# SMS0_DMTIMER_2_DMTIMER2 register map
Vendor: Texas Instruments
Peripheral module from a debugger description file (folder am62P).
Registers are 32-bit, read-write, reset 0x0 unless marked. A register's access mark holds for its fields unless they carry their own. Offsets are as the file gives them; lines under a group give offsets from that group; [hi:lo] are bit positions; {n}, {i} and the like mark numbered series; 'fields as' and 'values as' point back to an identical list; <NAME> marks a mode.

## SMS0_DMTIMER_2_DMTIMER2
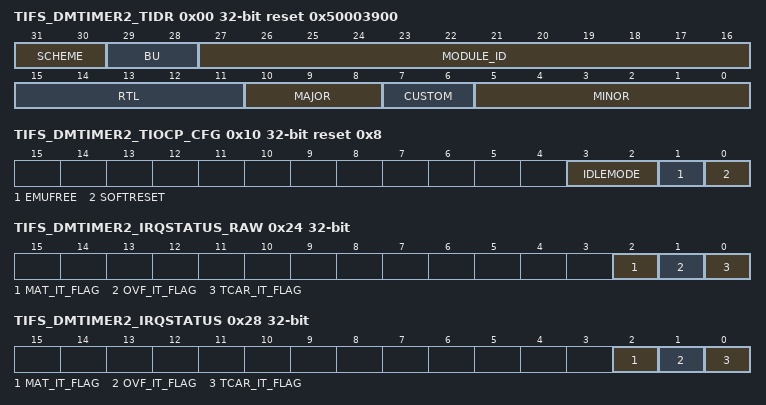
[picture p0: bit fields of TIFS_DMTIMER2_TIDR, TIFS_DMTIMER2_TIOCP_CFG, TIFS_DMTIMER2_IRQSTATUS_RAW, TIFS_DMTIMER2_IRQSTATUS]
0x00 TIFS_DMTIMER2_TIDR ro reset 0x50003900
  [31:30] SCHEME — PID register scheme
  [29:28] BU — Business Unit
  [27:16] MODULE_ID
  [15:11] RTL — RTL revision. Will vary depending on release.
  [10:8] MAJOR — Major revision
  [7:6] CUSTOM
  [5:0] MINOR — Minor revision
0x10 TIFS_DMTIMER2_TIOCP_CFG reset 0x8 — This register controls the various parameters of the OCP interface
  [3:2] IDLEMODE
  [1] EMUFREE — Emulation Mode
  [0] SOFTRESET — Software reset
0x20 TIFS_DMTIMER2_IRQ_EOI — Allows the generation of further pulses on the interrupt line, if an new interrupt event is pending, when using the pulsed output. Unused when using the level interrupt line
  [0] LINE_NUMBER — Idle Mode
0x24 TIFS_DMTIMER2_IRQSTATUS_RAW access not given — Component interrupt request status. Check the corresponding secondary status register. Raw status is set even if event is not enabled. Write 1 to set the (raw) status, mostly for debug
  [2] MAT_IT_FLAG — Match Interrupt (access R/W1TS)
  [1] OVF_IT_FLAG — Overflow Interrupt (access R/W1TS)
  [0] TCAR_IT_FLAG — Capture Interrupt (access R/W1TS)
0x28 TIFS_DMTIMER2_IRQSTATUS access not given — Component interrupt request status. Check the corresponding secondary status register.Enabled status isn't set unless event is enabled.Write 1 to clear the status after interrupt has been serviced;raw status gets cleared, i.e. even if not enabled
  [2] MAT_IT_FLAG — Match Interrupt (access R/W1TC)
  [1] OVF_IT_FLAG — Overflow Interrupt (access R/W1TC)
  [0] TCAR_IT_FLAG — Capture Interrupt (access R/W1TC)
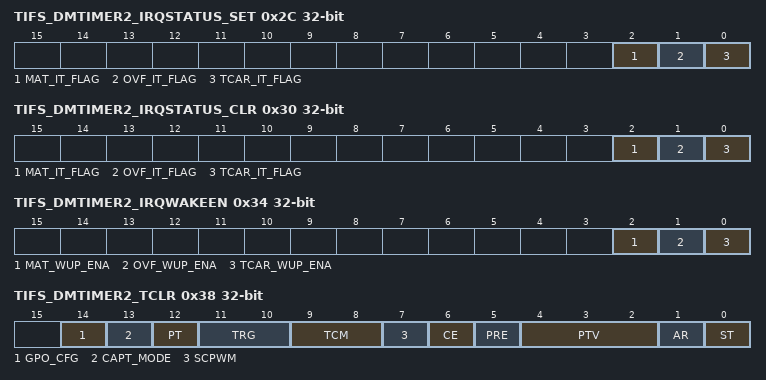
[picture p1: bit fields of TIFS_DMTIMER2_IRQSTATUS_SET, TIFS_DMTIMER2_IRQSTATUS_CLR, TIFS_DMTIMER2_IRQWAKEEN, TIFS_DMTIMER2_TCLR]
0x2C TIFS_DMTIMER2_IRQSTATUS_SET access not given — Component interrupt request enable Write 1 to set, enable interrupt. Readout equal to corresponding _CLR register.
  fields as TIFS_DMTIMER2_IRQSTATUS_RAW
0x30 TIFS_DMTIMER2_IRQSTATUS_CLR access not given — Component interrupt request enable. Write 1 to clear, disable interrupt. Readout equal to corresponding _SET register
  fields as TIFS_DMTIMER2_IRQSTATUS
0x34 TIFS_DMTIMER2_IRQWAKEEN — Wakeup-enabled events taking place when module is idle shall generate an asynchronous wakeup
  [2] MAT_WUP_ENA — Match Wakeup Enable
  [1] OVF_WUP_ENA — Overflow Wakeup Enable
  [0] TCAR_WUP_ENA — Capture Wakeup Enable
0x38 TIFS_DMTIMER2_TCLR — This register controls optional features specific to the timer functionality
  [14] GPO_CFG — This field drives directly the PO_GPOCFG pin
  [13] CAPT_MODE — Capture mode select bit; First/second
  [12] PT — Pulse or Toggle select bit
  [11:10] TRG — Trigger Output Mode
  [9:8] TCM — Transition Capture Mode
  [7] SCPWM — Pulse Width Modulation output pin default value
  [6] CE — Compare Enable
  [5] PRE — Prescaler Enable
  [4:2] PTV — Trigger Output Mode. The timer counter is prescaled with the value: 2^PTV
  [1] AR — Auto-reload mode
  [0] ST — Start/Stop timer control
0x3C TIFS_DMTIMER2_TCRR — This register holds the value of the internal counter
  [31:0] TIMER_COUNTER
0x40 TIFS_DMTIMER2_TLDR — This register holds the timer's load value
  [31:0] LOAD_VALUE — Timer Counter
0x44 TIFS_DMTIMER2_TTGR — This register triggers a counter reload of timer by writing any value in it
  [31:0] TTRG_VLAUE — The value of the trigger register. During reads, it always return 0xFFFF_FFFF
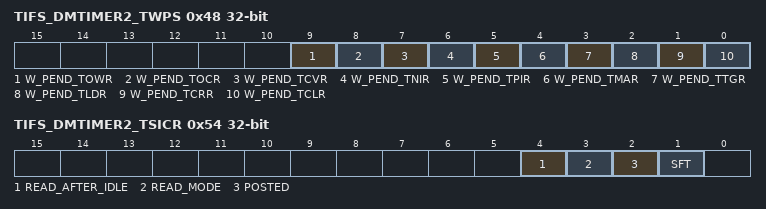
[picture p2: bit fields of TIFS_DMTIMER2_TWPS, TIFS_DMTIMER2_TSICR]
0x48 TIFS_DMTIMER2_TWPS ro — This register contains the write posting bits for all writ-able functional registers
  [9] W_PEND_TOWR — Write pending for register TOWR
  [8] W_PEND_TOCR — Write pending for register TOCR
  [7] W_PEND_TCVR — Write pending for register TCVR
  [6] W_PEND_TNIR — Write pending for register TNIR
  [5] W_PEND_TPIR — Write pending for register TPIR
  [4] W_PEND_TMAR — Write pending for register TMAR
  [3] W_PEND_TTGR — Write pending for register TTGR
  [2] W_PEND_TLDR — Write pending for register TLDR
  [1] W_PEND_TCRR — Write pending for register TCRR
  [0] W_PEND_TCLR — Write pending for register TCLR
0x4C TIFS_DMTIMER2_TMAR — This register holds the match value to be compared with the counter's value
  [31:0] COMPARE_VLAUE — The value of the match register
0x50 TIFS_DMTIMER2_TCAR1 ro — This register holds the value of the first counter register capture
  [31:0] CAPTURE_VALUE1 — The value of first captured counter register
0x54 TIFS_DMTIMER2_TSICR access per field — Timer Synchronous Interface Control Register
  [4] READ_AFTER_IDLE wo — Select if the synchronization mechanism used for first TCRR read operation after IDLE state is active
  [3] READ_MODE wo — Select posted/non-posted mode for read operation. This bit is not used when configured in posted mode
  [2] POSTED rw — Reset value of POSTED depends on hardware integration module at design time. Software must read POSTED field to get the hardwar module configuration
  [1] SFT rw — This bit reset all the functional part of teh module
0x58 TIFS_DMTIMER2_TCAR2 ro — This register holds the value of the second counter register capture
  [31:0] CAPTURE_VALUE2 — The value of second captured counter register
0x5C TIFS_DMTIMER2_TPIR — This register is used for 1ms tick generation. The TPIR register holds the value of the positive increment. The value of this register is added with the value of the TCVR to define whether next value loaded in TCRR will be the sub-period value or the over-period value
  [31:0] POSITIVE_INC_VALUE — The value of the positive increment
0x60 TIFS_DMTIMER2_TNIR — This register is used for 1ms tick generation. The TNIR register holds the value of the negative increment. The value of this register is added with the value of the TCVR to define whether next value loaded in TCRR will be the sub-period value or the over-period value
  [31:0] NEGATIVE_INC_VALUE — The value of the negative increment
0x64 TIFS_DMTIMER2_TCVR — This register is used for 1ms tick generation. The TCVR register defines whether next value loaded in TCRR will be the sub-period value or the over-period value
  [31:0] COUNTER_VALUE — The value of CVR counter
0x68 TIFS_DMTIMER2_TOCR — This register is used to mask the tick interrupt for a selected number of ticks
  [23:0] OVF_COUNTER_VALUE — The number of overflow events
0x6C TIFS_DMTIMER2_TOWR — This register holds the number of masked overflow interrupts
  [23:0] OVF_WRAPPING_VALUE — The number of masked interrupts
